AUTOSAR XML (schema 4-2-2)
package /Components
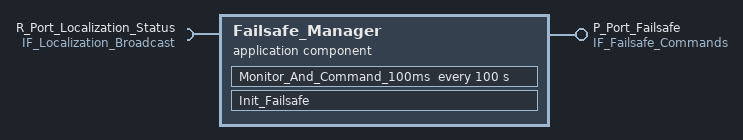
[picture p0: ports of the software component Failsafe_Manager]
  application sw component type Failsafe_Manager
    provide port P_Port_Failsafe: provided-interface=IF_Failsafe_Commands
    require port R_Port_Localization_Status: required-interface=IF_Localization_Broadcast
    behavior Failsafe_Manager_InternalBehavior
      init event Failsafe_Init: start-on-event=Init_Failsafe
      timing event Failsafe_100ms: start-on-event=Monitor_And_Command_100ms, period=100
      runnable Init_Failsafe
        parameter access InitParamAccess_Failsafe_Config: accessed-parameter=P_Port_Failsafe.Failsafe_Status
      runnable Monitor_And_Command_100ms: minimum-start-interval=100
        data-receive-point-by-arguments:
          access Read_Localization_Status: accessed-variable=R_Port_Localization_Status.Localization_Status
        data-send-points:
          access Send_MRC_Command: accessed-variable=P_Port_Failsafe.MRC_Command
          access Send_SOS_Command: accessed-variable=P_Port_Failsafe.SOS_Command
          access Send_Failsafe_Status: accessed-variable=P_Port_Failsafe.Failsafe_Status
